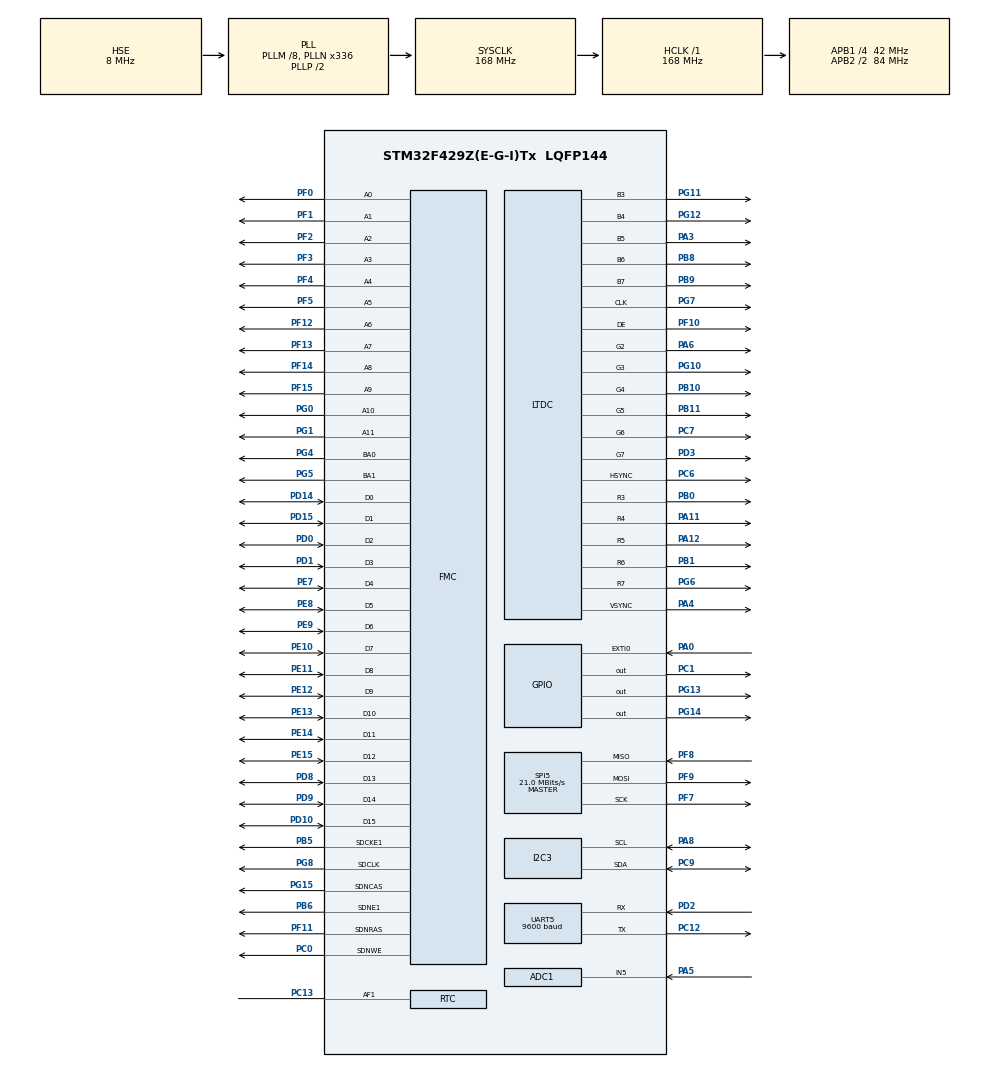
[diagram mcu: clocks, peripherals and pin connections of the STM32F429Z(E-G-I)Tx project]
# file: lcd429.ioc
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ADC1.Channel-20\#ChannelRegularConversion=ADC_CHANNEL_5
ADC1.Channel-28\#ChannelRegularConversion=ADC_CHANNEL_5
ADC1.Channel-29\#ChannelRegularConversion=ADC_CHANNEL_VBAT
ADC1.Channel-30\#ChannelRegularConversion=ADC_CHANNEL_VBAT
ADC1.ClockPrescaler=ADC_CLOCKPRESCALER_PCLK_DIV4
ADC1.ContinuousConvMode=ENABLE
ADC1.DMAContinuousRequests=ENABLE
ADC1.DataAlign=ADC_DATAALIGN_RIGHT
ADC1.DiscontinuousConvMode=DISABLE
ADC1.EOCSelection=EOC_SINGLE_CONV
ADC1.EnableAnalogWatchDog=false
ADC1.ExternalTrigConvEdge=ADC_EXTERNALTRIGCONVEDGE_NONE
ADC1.InjNumberOfConversion=0
ADC1.NbrOfConversion=4
ADC1.NbrOfConversionFlag=1
ADC1.Rank-20\#ChannelRegularConversion=1
ADC1.Rank-28\#ChannelRegularConversion=2
ADC1.Rank-29\#ChannelRegularConversion=3
ADC1.Rank-30\#ChannelRegularConversion=4
ADC1.Resolution=ADC_RESOLUTION12b
ADC1.SamplingTime-20\#ChannelRegularConversion=ADC_SAMPLETIME_3CYCLES
ADC1.SamplingTime-28\#ChannelRegularConversion=ADC_SAMPLETIME_3CYCLES
ADC1.SamplingTime-29\#ChannelRegularConversion=ADC_SAMPLETIME_3CYCLES
ADC1.SamplingTime-30\#ChannelRegularConversion=ADC_SAMPLETIME_3CYCLES
ADC1.ScanConvMode=ENABLE
ADC1.master=1
DMA2D.ColorMode=DMA2D_RGB565
DMA2D.Mode=DMA2D_R2M
Dma.ADC1.0.Channel=DMA_CHANNEL_0
Dma.ADC1.0.Direction=DMA_PERIPH_TO_MEMORY
Dma.ADC1.0.FIFOMode=DMA_FIFOMODE_DISABLE
Dma.ADC1.0.FIFOThreshold=DMA_FIFO_THRESHOLD_FULL
Dma.ADC1.0.Instance=DMA2_Stream0
Dma.ADC1.0.MemBurst=DMA_MBURST_SINGLE
Dma.ADC1.0.MemDataAlignment=DMA_MDATAALIGN_WORD
Dma.ADC1.0.MemInc=DMA_MINC_ENABLE
Dma.ADC1.0.Mode=DMA_NORMAL
Dma.ADC1.0.PeriphBurst=DMA_PBURST_SINGLE
Dma.ADC1.0.PeriphDataAlignment=DMA_PDATAALIGN_WORD
Dma.ADC1.0.PeriphInc=DMA_PINC_DISABLE
Dma.ADC1.0.Priority=DMA_PRIORITY_LOW
Dma.Request0=ADC1
FMC.CASLatency1=FMC_SDRAM_CAS_LATENCY_3
FMC.ExitSelfRefreshDelay1=7
FMC.LoadToActiveDelay1=2
FMC.RCDDelay1=2
FMC.RPDelay1=2
FMC.RPDelay2=2
FMC.RowBitsNumber1=FMC_SDRAM_ROW_BITS_NUM_12
FMC.RowCycleDelay1=7
FMC.RowCycleDelay2=7
FMC.SDClockPeriod1=FMC_SDRAM_CLOCK_PERIOD_2
FMC.SelfRefreshTime1=4
FMC.WriteRecoveryTime1=3
LTDC.ActiveH=320
LTDC.ActiveW=240
LTDC.Alpha_L0=255
LTDC.Alpha_L1=255
LTDC.BlendingFactor1_L0=LTDC_BLENDING_FACTOR1_PAxCA
LTDC.BlendingFactor1_L1=LTDC_BLENDING_FACTOR1_PAxCA
LTDC.BlendingFactor2_L0=LTDC_BLENDING_FACTOR2_PAxCA
LTDC.BlendingFactor2_L1=LTDC_BLENDING_FACTOR2_PAxCA
LTDC.FBStartAdress_L0=0xD0000000
LTDC.FBStartAdress_L1=0xD0025800
LTDC.HBP=29
LTDC.HFP=2
LTDC.HSync=9
LTDC.ImageHeight_L0=320
LTDC.ImageHeight_L1=320
LTDC.ImageWidth_L0=240
LTDC.ImageWidth_L1=240
LTDC.VBP=3
LTDC.VSync=1
LTDC.WindowX1_L0=240
LTDC.WindowX1_L1=240
LTDC.WindowY1_L0=320
LTDC.WindowY1_L1=320
Mcu.Family=STM32F4
Mcu.Name=STM32F429Z(E-G-I)Tx
Mcu.Package=LQFP144
NVIC.ADC_IRQn=true\:0\:0\:false
NVIC.DMA2_Stream0_IRQn=true\:0\:0\:false
NVIC.EXTI0_IRQn=true\:0\:0\:false
NVIC.PriorityGroup=NVIC_PRIORITYGROUP_4
PA0/WKUP.Signal=GPXTI0
PA11.Mode=RGB565
PA11.Signal=LTDC_R4
PA12.Mode=RGB565
PA12.Signal=LTDC_R5
PA3.Mode=RGB565
PA3.Signal=LTDC_B5
PA4.Mode=RGB565
PA4.Signal=LTDC_VSYNC
PA5.Signal=ADCx_IN5
PA6.Mode=RGB565
PA6.Signal=LTDC_G2
PA8.Mode=I2C
PA8.Signal=I2C3_SCL
PB0.Mode=RGB565
PB0.Signal=LTDC_R3
PB1.Mode=RGB565
PB1.Signal=LTDC_R6
PB10.Mode=RGB565
PB10.Signal=LTDC_G4
PB11.Mode=RGB565
PB11.Signal=LTDC_G5
PB5.Mode=SdramChipSelect2_1
PB5.Signal=FMC_SDCKE1
PB6.Mode=SdramChipSelect2_1
PB6.Signal=FMC_SDNE1
PB8.Mode=RGB565
PB8.Signal=LTDC_B6
PB9.Mode=RGB565
PB9.Signal=LTDC_B7
PC0.Signal=FMC_SDNWE
PC1.Signal=GPIO_Output
PC12.Mode=Asynchronous
PC12.Signal=UART5_TX
PC13.Mode=Timestamp enabled - Input Enabled to AF1
PC13.Signal=RTC_AF1
PC6.Mode=RGB565
PC6.Signal=LTDC_HSYNC
PC7.Mode=RGB565
PC7.Signal=LTDC_G6
PC9.Mode=I2C
PC9.Signal=I2C3_SDA
PD0.Signal=FMC_D2_DA2
PD1.Signal=FMC_D3_DA3
PD10.Signal=FMC_D15_DA15
PD14.Signal=FMC_D0_DA0
PD15.Signal=FMC_D1_DA1
PD2.Mode=Asynchronous
PD2.Signal=UART5_RX
PD3.Mode=RGB565
PD3.Signal=LTDC_G7
PD8.Signal=FMC_D13_DA13
PD9.Signal=FMC_D14_DA14
PE10.Signal=FMC_D7_DA7
PE11.Signal=FMC_D8_DA8
PE12.Signal=FMC_D9_DA9
PE13.Signal=FMC_D10_DA10
PE14.Signal=FMC_D11_DA11
PE15.Signal=FMC_D12_DA12
PE7.Signal=FMC_D4_DA4
PE8.Signal=FMC_D5_DA5
PE9.Signal=FMC_D6_DA6
PF0.Signal=FMC_A0
PF1.Signal=FMC_A1
PF10.Mode=RGB565
PF10.Signal=LTDC_DE
PF11.Signal=FMC_SDNRAS
PF12.Signal=FMC_A6
PF13.Signal=FMC_A7
PF14.Signal=FMC_A8
PF15.Signal=FMC_A9
PF2.Signal=FMC_A2
PF3.Signal=FMC_A3
PF4.Signal=FMC_A4
PF5.Signal=FMC_A5
PF7.Mode=Full_Duplex_Master
PF7.Signal=SPI5_SCK
PF8.Mode=Full_Duplex_Master
PF8.Signal=SPI5_MISO
PF9.Mode=Full_Duplex_Master
PF9.Signal=SPI5_MOSI
PG0.Signal=FMC_A10
PG1.Signal=FMC_A11
PG10.Mode=RGB565
PG10.Signal=LTDC_G3
PG11.Mode=RGB565
PG11.Signal=LTDC_B3
PG12.Mode=RGB565
PG12.Signal=LTDC_B4
PG13.Signal=GPIO_Output
PG14.Signal=GPIO_Output
PG15.Signal=FMC_SDNCAS
PG4.Signal=FMC_A14_BA0
PG5.Signal=FMC_A15_BA1
PG6.Mode=RGB565
PG6.Signal=LTDC_R7
PG7.Mode=RGB565
PG7.Signal=LTDC_CLK
PG8.Signal=FMC_SDCLK
PH0/OSC_IN.Mode=HSE-External-Oscillator
PH0/OSC_IN.Signal=RCC_OSC_IN
PH1/OSC_OUT.Mode=HSE-External-Oscillator
PH1/OSC_OUT.Signal=RCC_OSC_OUT
ProjectManager.TargetToolchain=MDK-ARM V5
RCC.48MHZClocksFreq_Value=84000000
RCC.AHBFreq_Value=168000000
RCC.APB1CLKDivider=RCC_HCLK_DIV4
RCC.APB1Freq_Value=42000000
RCC.APB1TimFreq_Value=84000000
RCC.APB2CLKDivider=RCC_HCLK_DIV2
RCC.APB2Freq_Value=84000000
RCC.APB2TimFreq_Value=168000000
RCC.CortexFreq_Value=168000000
RCC.HCLKFreq_Value=168000000
RCC.HSE_VALUE=8000000
RCC.HSI_VALUE=16000000
RCC.PLLM=8
RCC.PLLN=336
RCC.PLLSAIDivR=RCC_PLLSAIDIVR_4
RCC.PLLSAIN=192
RCC.PLLSAIR=5
RCC.PLLSourceVirtual=RCC_PLLSOURCE_HSE
RCC.SYSCLKFreq_VALUE=168000000
RCC.SYSCLKSource=RCC_SYSCLKSOURCE_PLLCLK
RCC.VCOOutputFreq_Value=336000000
RTC.Date=30
RTC.Format=FORMAT_BIN
RTC.Hours=12
RTC.Month=RTC_MONTH_DECEMBER
RTC.Year=15
SH.ADCx_IN5.0=ADC1_IN5,IN5
SH.FMC_A0.0=FMC_A0,12b-sda1
SH.FMC_A1.0=FMC_A1,12b-sda1
SH.FMC_A10.0=FMC_A10,12b-sda1
SH.FMC_A11.0=FMC_A11,12b-sda1
SH.FMC_A14_BA0.0=FMC_BA0,FourSdramBanks1
SH.FMC_A15_BA1.0=FMC_BA1,FourSdramBanks1
SH.FMC_A2.0=FMC_A2,12b-sda1
SH.FMC_A3.0=FMC_A3,12b-sda1
SH.FMC_A4.0=FMC_A4,12b-sda1
SH.FMC_A5.0=FMC_A5,12b-sda1
SH.FMC_A6.0=FMC_A6,12b-sda1
SH.FMC_A7.0=FMC_A7,12b-sda1
SH.FMC_A8.0=FMC_A8,12b-sda1
SH.FMC_A9.0=FMC_A9,12b-sda1
SH.FMC_D0_DA0.0=FMC_D0,sd-16b-d1
SH.FMC_D10_DA10.0=FMC_D10,sd-16b-d1
SH.FMC_D11_DA11.0=FMC_D11,sd-16b-d1
SH.FMC_D12_DA12.0=FMC_D12,sd-16b-d1
SH.FMC_D13_DA13.0=FMC_D13,sd-16b-d1
SH.FMC_D14_DA14.0=FMC_D14,sd-16b-d1
SH.FMC_D15_DA15.0=FMC_D15,sd-16b-d1
SH.FMC_D1_DA1.0=FMC_D1,sd-16b-d1
SH.FMC_D2_DA2.0=FMC_D2,sd-16b-d1
SH.FMC_D3_DA3.0=FMC_D3,sd-16b-d1
SH.FMC_D4_DA4.0=FMC_D4,sd-16b-d1
SH.FMC_D5_DA5.0=FMC_D5,sd-16b-d1
SH.FMC_D6_DA6.0=FMC_D6,sd-16b-d1
SH.FMC_D7_DA7.0=FMC_D7,sd-16b-d1
SH.FMC_D8_DA8.0=FMC_D8,sd-16b-d1
SH.FMC_D9_DA9.0=FMC_D9,sd-16b-d1
SH.FMC_SDCLK.0=FMC_SDCLK,12b-sda1
SH.FMC_SDNCAS.0=FMC_SDNCAS,12b-sda1
SH.FMC_SDNRAS.0=FMC_SDNRAS,12b-sda1
SH.FMC_SDNWE.0=FMC_SDNWE,12b-sda1
SPI5.BaudRatePrescaler=SPI_BAUDRATEPRESCALER_4
SPI5.CalculateBaudRate=21.0 MBits/s
SPI5.Mode=SPI_MODE_MASTER
UART5.BaudRate=9600
VP_ADC1_Vbat_Input.Mode=IN-Vbat
VP_DMA2D_VS_DMA2D.Mode=DMA2D_Activate
board=lcd429

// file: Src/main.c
/**
  ******************************************************************************
  * File Name          : main.c
  * Description        : Main program body
  ******************************************************************************
  *
  * COPYRIGHT(c) 2015 STMicroelectronics
  *
  * Redistribution and use in source and binary forms, with or without modification,
  * are permitted provided that the following conditions are met:
  *   1. Redistributions of source code must retain the above copyright notice,
  *      this list of conditions and the following disclaimer.
  *   2. Redistributions in binary form must reproduce the above copyright notice,
  *      this list of conditions and the following disclaimer in the documentation
  *      and/or other materials provided with the distribution.
  *   3. Neither the name of STMicroelectronics nor the names of its contributors
  *      may be used to endorse or promote products derived from this software
  *      without specific prior written permission.
  *
  * THIS SOFTWARE IS PROVIDED BY THE COPYRIGHT HOLDERS AND CONTRIBUTORS "AS IS"
  * AND ANY EXPRESS OR IMPLIED WARRANTIES, INCLUDING, BUT NOT LIMITED TO, THE
  * IMPLIED WARRANTIES OF MERCHANTABILITY AND FITNESS FOR A PARTICULAR PURPOSE ARE
  * DISCLAIMED. IN NO EVENT SHALL THE COPYRIGHT HOLDER OR CONTRIBUTORS BE LIABLE
  * FOR ANY DIRECT, INDIRECT, INCIDENTAL, SPECIAL, EXEMPLARY, OR CONSEQUENTIAL
  * DAMAGES (INCLUDING, BUT NOT LIMITED TO, PROCUREMENT OF SUBSTITUTE GOODS OR
  * SERVICES; LOSS OF USE, DATA, OR PROFITS; OR BUSINESS INTERRUPTION) HOWEVER
  * CAUSED AND ON ANY THEORY OF LIABILITY, WHETHER IN CONTRACT, STRICT LIABILITY,
  * OR TORT (INCLUDING NEGLIGENCE OR OTHERWISE) ARISING IN ANY WAY OUT OF THE USE
  * OF THIS SOFTWARE, EVEN IF ADVISED OF THE POSSIBILITY OF SUCH DAMAGE.
  *
  ******************************************************************************
  */
#include "stm32f4xx_hal.h"

/* USER CODE BEGIN Includes */
#include "pin.h"
#include "sdram.h"
#include "ili9341.h"
//#include "graph.h"
#include "l3gd20.h"
#include "itg3200.h"
#include "hmc5883.h"
#include "adxl345.h"
#include "compas.h"
#include "clinometer.h"
#include "guage.h"
#include "math.h"
#include "ff.h"
#include "image.h"

/* USER CODE END Includes */

ADC_HandleTypeDef hadc1;
DMA_HandleTypeDef hdma_adc1;

DMA2D_HandleTypeDef hdma2d;

I2C_HandleTypeDef hi2c3;

LTDC_HandleTypeDef hltdc;

RTC_HandleTypeDef hrtc;

SPI_HandleTypeDef hspi5;

UART_HandleTypeDef huart5;

SDRAM_HandleTypeDef hsdram1;

/* USER CODE BEGIN PV */
/* Private variables ---------------------------------------------------------*/

uint8_t flagButton;
char str[] = "1.0.1";
char bufStr[50] = "";
const char *directions[17]={"N","NNE","NE","ENE",
														"E","ESE","SE","SSE",
														"S","SSW","SW","WSW",
														"W","WNW","NW","NNW","N"};

__IO uint32_t TM_Time2;

/* USER CODE END PV */

void SystemClock_Config(void);
static void MX_GPIO_Init(void);
static void MX_DMA_Init(void);
static void MX_ADC1_Init(void);
static void MX_DMA2D_Init(void);
static void MX_FMC_Init(void);
static void MX_I2C3_Init(void);
static void MX_LTDC_Init(void);
static void MX_RTC_Init(void);
static void MX_SPI5_Init(void);
static void MX_UART5_Init(void);

/* USER CODE BEGIN PFP */
/* Private function prototypes -----------------------------------------------*/

/* USER CODE END PFP */

int main(void)
{

  /* USER CODE BEGIN 1 */
	uint8_t mode = 0, r, temp;
	uint8_t firsttime = 0, tosave = 0;
	uint32_t cur_tick, tmp_tick;
	//L3GD20_t lxyz;
	uint32_t i;
	XYZ_t ixyz, txyz;
	HMC_ID_StructTypeDef hres;
	int32_t tmp;
	int32_t tmpV, clV, valV;
	float angl;
	//uint16_t i;
  uint32_t adcData[5];

	FATFS FS;
	FRESULT fres;
	FATFS *fs;
	uint32_t Total; /*!< Total size of memory */
	uint32_t Free;  /*!< Free size of memory */

	DWORD fre_clust;

	DIR dir;
	FILINFO fno;

	FIL fil;
	UINT nWritten;
	UINT toWrite;
	UINT totalWrite;
	UINT totalWriten;

	BITMAPFILEHEADER bfh;
	BITMAPINFOHEADER bih;

	RTC_TimeTypeDef sTime;
	RTC_DateTypeDef sDate;

  /* USER CODE END 1 */

  /* MCU Configuration----------------------------------------------------------*/

  /* Reset of all peripherals, Initializes the Flash interface and the Systick. */
  HAL_Init();

  /* Configure the system clock */
  SystemClock_Config();

  /* Initialize all configured peripherals */
  MX_GPIO_Init();
  MX_DMA_Init();
  MX_ADC1_Init();
  MX_DMA2D_Init();
  MX_FMC_Init();
  MX_I2C3_Init();
  MX_LTDC_Init();
  MX_RTC_Init();
  MX_SPI5_Init();
  MX_UART5_Init();

  /* USER CODE BEGIN 2 */
	GPIO_HIGH(L3GD20_CS_PORT, L3GD20_CS_PIN);
	GPIO_HIGH(GPIOF, GPIO_PIN_6);//FATFS_CS_PORT, FATFS_CS_PIN

	//SPI_Init_Pins();

	SDRAM_InitPins();
 	SDRAM_Init(&hsdram1);
	//if (SDRAM_Init(&hsdram1)) GPIO_TOGGLE(GPIOG, GPIO_PIN_14);

	ILI9341_InitPins();
	ILI9341_Init();
	HAL_LTDC_SetAlpha(&hltdc, 255, 0);
	HAL_LTDC_SetAlpha(&hltdc, 0, 1);

	GRPH_Init();
	DMA2DGRPH_Fill();

	GRPH_DrawRect(0, 0, 239, 319);
//	GRPH_DrawLine(0,0,239,319);
//	GRPH_DrawLine(239,0,0,319);
//	GRPH_DrawCircle(120,160,60);

	DrawCompas(22, 297, 20, 0, 0);
	DrawClinometer(64, 297, 20, 0, 0);
	DrawGuageAbsolut(88, 297, 20, 100, 0, GRPH_COLOR_RED);

	GRPH_SetXY(200, 309);
	GRPH_Puts(str);

	HMC_Init(HMC_MR_CMM, HMC_DR_15, HMC_MM_Normal, HMC_GS_4_0, HMC_SS_1);
	L3GD20_Init(L3GD20_Scale_250);
	ITG_Init(ITG_DLPF_20_1, 0, ITG_CLK_GyroX);
	ADXL_Init();

	//HAL_ADC_Start(&hadc1);
	HAL_ADC_Start_DMA(&hadc1, adcData, 4);
	//ITG_SetChipAddr(0xd0);

//	if (f_mount(&FS, "0", 1) == FR_OK) {
//			fres = f_opendir(&dir, "/");
//			f_mount(NULL, "0", 1);
//	}

  /* USER CODE END 2 */

  /* Infinite loop */
  while (1)
  {

  /* USER CODE BEGIN 3 */

		cur_tick = HAL_GetTick();
		if (cur_tick - tmp_tick > 200){

			if (mode == 0 || mode == 1){

//				HAL_ADC_Start_DMA(&hadc1, adcData, 5);
				//HAL_ADC_GetValue(&hadc1);

				r = L3GD20_INT_ReadSPI(L3GD20_REG_WHO_AM_I);
				L3GD20_Read(&ixyz);
				sprintf(bufStr, "%02x %6d; %6d; %6d;", r, ixyz.X, ixyz.Y, ixyz.Z);
				//HAL_UART_Transmit(&huart5, (uint8_t *) bufStr, 50, 100);
				GRPH_SetXY(2, 3);
				GRPH_Puts(bufStr);

				r = ITG_GetChipAddr();
				ITG_GetXYZ(&ixyz);
				temp = ITG_GetTemperature();
				temp = ITG_ConvTemp(temp);
				sprintf(bufStr, "%02x %6d; %6d; %6d; %3d", r, ixyz.X, ixyz.Y, ixyz.Z, temp);
				GRPH_SetXY(2, 14);
				GRPH_Puts(bufStr);

				//GRPH_DrawPixel(80 + ixyz.X, 100 + ixyz.Y);

				HMC_GetId(&hres);
				HMC_GetXYZ(&ixyz);
				sprintf(bufStr, "%c%c%c %5d; %6d; %6d", hres.VALA, hres.VALB, hres.VALC, ixyz.X, ixyz.Y, ixyz.Z);
				GRPH_SetXY(2, 26);
				GRPH_Puts(bufStr);

				//DrawCompas(22, 297, 20, hxyz.X, hxyz.Y);
				DrawCompas(52, 100, 50, ixyz.X, ixyz.Y);

				angl = 270 + atan2(ixyz.Y, ixyz.X) * 180 /3.14;
				if (angl > 360) angl -= 360;
				tmp = (angl + 11)/22.5;
				sprintf(bufStr, "%4.1f %s      ", angl, directions[tmp]);
				GRPH_SetXY(2, 154);
				GRPH_Puts(bufStr);

				DrawGuage(107, 100, 50, ixyz.X, txyz.X, GRPH_COLOR_GREEN);
				DrawGuage(114, 100, 50, ixyz.Y, txyz.Y, GRPH_COLOR_BLUE);
				DrawGuage(121, 100, 50, ixyz.Z, txyz.Z, GRPH_COLOR_YELLOW);
				txyz.X = ixyz.X;
				txyz.Y = ixyz.Y;
				txyz.Z = ixyz.Z;

				r = ADXL_GetDeviceId();
				ADXL_GetXYZ(&ixyz);
				sprintf(bufStr, "%x %6d; %6d; %6d", r, ixyz.X, ixyz.Y, ixyz.Z);
				GRPH_SetXY(2, 38);
				GRPH_Puts(bufStr);
				//DrawClinometer(64, 297, 20, axyz.Y, 0);

				DrawClinometer(176, 100, 50, ixyz.X, ixyz.Y);

//				sprintf(bufStr, "%4x; %4x; %4x; %4x; %4x", adcData[0], adcData[1], adcData[2], adcData[3], adcData[4]);
//				//sprintf(bufStr, "%2.1fV %x     ", (3.3*(adcData[0]+adcData[1]+adcData[2]))/0x0fff/3, (adcData[0]+adcData[1]+adcData[2])/3);
//				GRPH_SetXY(2, 166);
//				GRPH_Puts(bufStr);
//
//				//sprintf(bufStr, "%4x; %4x; %4x; %4x; %4x", adcData[0], adcData[1], adcData[2], adcData[3], adcData[4]);
//				sprintf(bufStr, "%2.1fV %2.1fV     ", (3.3*(adcData[0]+adcData[1]+adcData[2]))/0x0fff/3, (3.3*(adcData[3]+adcData[4]))/0x0fff/2);
//				GRPH_SetXY(2, 178);
//				GRPH_Puts(bufStr);
//
//				if (adcData[0]> 0x500) clV = GRPH_COLOR_GREEN;
//				else  clV = GRPH_COLOR_RED;
//				valV = (adcData[0]+adcData[1]+adcData[2])/0x0f/3;
//				DrawBattery(220, 40, 10, valV, tmpV, clV);
//				tmpV = valV;

				HAL_RTC_GetTime(&hrtc, &sTime, RTC_FORMAT_BIN);
				HAL_RTC_SetDate(&hrtc, &sDate, RTC_FORMAT_BIN);

				sprintf(bufStr, "%04d%02d%02d %02d:%02d:%02d ", sDate.Year, sDate.Month, sDate.Date,
				 sTime.Hours, sTime.Minutes, sTime.Seconds);
				GRPH_SetXY(2, 190);
				GRPH_Puts(bufStr);

//				HAL_ADC_Stop_DMA(&hadc1);

				if (tosave == 1){
//					fres = img_save();
					//fres = f_mount(&FS, "SD:", 1);
					totalWrite = LCD_PIXEL_WIDTH * LCD_PIXEL_HEIGHT * LCD_PIXEL_SIZE;

					GPIO_TOGGLE(GPIOG, GPIO_PIN_14);

					//memset (&bfh, 0, sizeof(bfh));
					bfh.bfType = 0x4D42;
					bfh.bfOffBits = sizeof(bfh) + sizeof(bih);
					bfh.bfSize = bfh.bfOffBits + totalWrite;
					//memset (&bih, 0, sizeof(bih));
					bih.biSize = sizeof(bih);
					bih.biBitCount = 16;
					bih.biClrUsed = 0;
					bih.biCompression = 0;
					bih.biHeight = LCD_PIXEL_HEIGHT;
					bih.biWidth = LCD_PIXEL_WIDTH;
					bih.biPlanes = 1;
						//sprintf(bufStr, "pointer  %u", (uint32_t) &bfh);
						//GRPH_SetXY(2, 205);
						//GRPH_Puts(bufStr);

					fres = f_mount(&FS, "0", 1);
					if (fres == FR_OK) {
						//fres = img_save();

						//fres = f_open(&fil, "img.raw", FA_OPEN_ALWAYS | FA_READ | FA_WRITE);
						fres = f_open(&fil, "img.bmp", FA_OPEN_ALWAYS | FA_READ | FA_WRITE);
						if (fres == FR_OK) {

							//f_write(&fil, (uint8_t *) &bfh, sizeof(bfh), &nWritten);
							//f_write(&fil, (uint8_t *)(&bih), sizeof(bih), &nWritten);

							nWritten = 0;
							totalWriten = 0;
							toWrite = totalWrite;
							while (totalWrite > totalWriten){

								f_write(&fil, (uint8_t *)(LCD_FRAME_BUFFER + totalWriten), toWrite, &nWritten);
								toWrite -= nWritten;
								totalWriten += nWritten;
								nWritten = 0;

							}
							f_close(&fil);
						}

						f_mount(NULL, "0", 1);
					}
					if (fres == FR_OK) {
						sprintf(bufStr, "Write OK   ");
						GRPH_SetXY(2, 205);
						GRPH_Puts(bufStr);
					}else{
						sprintf(bufStr, "Error:  %u ", fres);
						GRPH_SetXY(2, 205);
						GRPH_Puts(bufStr);
					}
					//fres = img_bmp_save();
					tosave = 0;
				}

			}

			i++;
			if (i >= 10) i=0;

			GPIO_TOGGLE(GPIOG, GPIO_PIN_13);
			tmp_tick = cur_tick;
		}

		if (firsttime && mode == 1) {

			tosave = 1;

		}

		if (firsttime && mode == 3) {

			//fres = img_read();
			if (f_mount(&FS, "0", 1) == FR_OK) {

					fres = f_open(&fil, "img.raw", FA_OPEN_EXISTING | FA_READ );
					if (fres == FR_OK) {

							f_read(&fil, (uint8_t *)(LCD_FRAME_BUFFER), LCD_PIXEL_WIDTH*LCD_PIXEL_WIDTH*LCD_PIXEL_SIZE, &nWritten);

							/* Close file */
							f_close(&fil);

					}

					/* Unmount SDCARD */
					f_mount(NULL, "SD:", 1);
			}
			if (fres == FR_OK) {
				sprintf(bufStr, "Read OK  ");
				GRPH_SetXY(2, 205);
				GRPH_Puts(bufStr);

			}else{
				sprintf(bufStr, "Error:  %u ", fres);
				GRPH_SetXY(2, 205);
				GRPH_Puts(bufStr);
			}
		}

		if (firsttime && mode == 2) {

			//if (f_mount(&FS, "SD:", 1) == FR_OK) {
			if (f_mount(&FS, "0", 1) == FR_OK) {

					if (f_getfree("SD:", &fre_clust, &fs) == FR_OK) {
							Total = (fs->n_fatent - 2) * fs->csize * 0.5;
							Free = fre_clust * fs->csize * 0.5;
					}

					sprintf(bufStr, "Total: %u kBytes", Total);
					GRPH_SetXY(2, 3);
					GRPH_Puts(bufStr);
					sprintf(bufStr, "Free:  %u kBytes", Free);
					GRPH_SetXY(2, 14);
					GRPH_Puts(bufStr);

					i = 2;
					//fres = f_opendir(&dir, "SD:");
					fres = f_opendir(&dir, "/");
					if (fres == FR_OK) {
						while ((fres = f_readdir(&dir, &fno)) == FR_OK && fno.fname[0] != 0) {
							sprintf(bufStr, "%s - %u", fno.fname, fno.fsize);
							GRPH_SetXY(2, 12 * i + 3);
							GRPH_Puts(bufStr);
							i++;
						}
						f_closedir(&dir);
					}else{
						sprintf(bufStr, "Error:  %u ", fres);
						GRPH_SetXY(2, 12 * i + 3);
						GRPH_Puts(bufStr);
						i++;
					}

					/* Unmount SDCARD */
					f_mount(NULL, "SD:", 1);
			}
		}

		firsttime = 0;
		if (flagButton == 1){
			mode++;
			firsttime = 1;
      GPIO_TOGGLE(GPIOG, GPIO_PIN_14);
			flagButton = 0;

			DMA2DGRPH_Fill();

			GRPH_DrawRect(0,0,239,319);

			GRPH_SetXY(200, 309);
			GRPH_Puts(str);
		}

		if (mode == 4) mode = 0;
  }
  /* USER CODE END 3 */

}

/** System Clock Configuration
*/
void SystemClock_Config(void)
{

  RCC_OscInitTypeDef RCC_OscInitStruct;
  RCC_ClkInitTypeDef RCC_ClkInitStruct;
  RCC_PeriphCLKInitTypeDef PeriphClkInitStruct;

  __PWR_CLK_ENABLE();

  __HAL_PWR_VOLTAGESCALING_CONFIG(PWR_REGULATOR_VOLTAGE_SCALE1);

  RCC_OscInitStruct.OscillatorType = RCC_OSCILLATORTYPE_LSI|RCC_OSCILLATORTYPE_HSE;
  RCC_OscInitStruct.HSEState = RCC_HSE_ON;
  RCC_OscInitStruct.LSIState = RCC_LSI_ON;
  RCC_OscInitStruct.PLL.PLLState = RCC_PLL_ON;
  RCC_OscInitStruct.PLL.PLLSource = RCC_PLLSOURCE_HSE;
  RCC_OscInitStruct.PLL.PLLM = 8;
  RCC_OscInitStruct.PLL.PLLN = 336;
  RCC_OscInitStruct.PLL.PLLP = RCC_PLLP_DIV2;
  RCC_OscInitStruct.PLL.PLLQ = 4;
  HAL_RCC_OscConfig(&RCC_OscInitStruct);

  RCC_ClkInitStruct.ClockType = RCC_CLOCKTYPE_SYSCLK|RCC_CLOCKTYPE_PCLK1
                              |RCC_CLOCKTYPE_PCLK2;
  RCC_ClkInitStruct.SYSCLKSource = RCC_SYSCLKSOURCE_PLLCLK;
  RCC_ClkInitStruct.AHBCLKDivider = RCC_SYSCLK_DIV1;
  RCC_ClkInitStruct.APB1CLKDivider = RCC_HCLK_DIV4;
  RCC_ClkInitStruct.APB2CLKDivider = RCC_HCLK_DIV2;
  HAL_RCC_ClockConfig(&RCC_ClkInitStruct, FLASH_LATENCY_5);

  PeriphClkInitStruct.PeriphClockSelection = RCC_PERIPHCLK_LTDC|RCC_PERIPHCLK_RTC;
  PeriphClkInitStruct.PLLSAI.PLLSAIN = 192;
  PeriphClkInitStruct.PLLSAI.PLLSAIR = 5;
  PeriphClkInitStruct.PLLSAIDivR = RCC_PLLSAIDIVR_4;
  PeriphClkInitStruct.RTCClockSelection = RCC_RTCCLKSOURCE_LSI;
  HAL_RCCEx_PeriphCLKConfig(&PeriphClkInitStruct);

  HAL_SYSTICK_Config(HAL_RCC_GetHCLKFreq()/1000);

  HAL_SYSTICK_CLKSourceConfig(SYSTICK_CLKSOURCE_HCLK);

  /* SysTick_IRQn interrupt configuration */
  HAL_NVIC_SetPriority(SysTick_IRQn, 0, 0);
}

/* ADC1 init function */
void MX_ADC1_Init(void)
{

  ADC_ChannelConfTypeDef sConfig;

    /**Configure the global features of the ADC (Clock, Resolution, Data Alignment and number of conversion)
    */
  hadc1.Instance = ADC1;
  hadc1.Init.ClockPrescaler = ADC_CLOCKPRESCALER_PCLK_DIV4;
  hadc1.Init.Resolution = ADC_RESOLUTION12b;
  hadc1.Init.ScanConvMode = ENABLE;
  hadc1.Init.ContinuousConvMode = ENABLE;
  hadc1.Init.DiscontinuousConvMode = DISABLE;
  hadc1.Init.ExternalTrigConvEdge = ADC_EXTERNALTRIGCONVEDGE_NONE;
  hadc1.Init.DataAlign = ADC_DATAALIGN_RIGHT;
  hadc1.Init.NbrOfConversion = 4;
  hadc1.Init.DMAContinuousRequests = ENABLE;
  hadc1.Init.EOCSelection = EOC_SINGLE_CONV;
  HAL_ADC_Init(&hadc1);

    /**Configure for the selected ADC regular channel its corresponding rank in the sequencer and its sample time.
    */
  sConfig.Channel = ADC_CHANNEL_5;
  sConfig.Rank = 1;
  sConfig.SamplingTime = ADC_SAMPLETIME_3CYCLES;
  HAL_ADC_ConfigChannel(&hadc1, &sConfig);

    /**Configure for the selected ADC regular channel its corresponding rank in the sequencer and its sample time.
    */
  sConfig.Rank = 2;
  HAL_ADC_ConfigChannel(&hadc1, &sConfig);

    /**Configure for the selected ADC regular channel its corresponding rank in the sequencer and its sample time.
    */
  sConfig.Channel = ADC_CHANNEL_VBAT;
  sConfig.Rank = 3;
  HAL_ADC_ConfigChannel(&hadc1, &sConfig);

    /**Configure for the selected ADC regular channel its corresponding rank in the sequencer and its sample time.
    */
  sConfig.Rank = 4;
  HAL_ADC_ConfigChannel(&hadc1, &sConfig);

}

/* DMA2D init function */
void MX_DMA2D_Init(void)
{

  hdma2d.Instance = DMA2D;
  hdma2d.Init.Mode = DMA2D_R2M;
  hdma2d.Init.ColorMode = DMA2D_RGB565;
  hdma2d.Init.OutputOffset = 0;
  HAL_DMA2D_Init(&hdma2d);

}

/* I2C3 init function */
void MX_I2C3_Init(void)
{

  hi2c3.Instance = I2C3;
  hi2c3.Init.ClockSpeed = 100000;
  hi2c3.Init.DutyCycle = I2C_DUTYCYCLE_2;
  hi2c3.Init.OwnAddress1 = 0;
  hi2c3.Init.AddressingMode = I2C_ADDRESSINGMODE_7BIT;
  hi2c3.Init.DualAddressMode = I2C_DUALADDRESS_DISABLED;
  hi2c3.Init.OwnAddress2 = 0;
  hi2c3.Init.GeneralCallMode = I2C_GENERALCALL_DISABLED;
  hi2c3.Init.NoStretchMode = I2C_NOSTRETCH_DISABLED;
  HAL_I2C_Init(&hi2c3);

}

/* LTDC init function */
void MX_LTDC_Init(void)
{

  LTDC_LayerCfgTypeDef pLayerCfg;
  LTDC_LayerCfgTypeDef pLayerCfg1;

  hltdc.Instance = LTDC;
  hltdc.Init.HSPolarity = LTDC_HSPOLARITY_AL;
  hltdc.Init.VSPolarity = LTDC_VSPOLARITY_AL;
  hltdc.Init.DEPolarity = LTDC_DEPOLARITY_AL;
  hltdc.Init.PCPolarity = LTDC_PCPOLARITY_IPC;
  hltdc.Init.HorizontalSync = 8;
  hltdc.Init.VerticalSync = 0;
  hltdc.Init.AccumulatedHBP = 37;
  hltdc.Init.AccumulatedVBP = 3;
  hltdc.Init.AccumulatedActiveW = 277;
  hltdc.Init.AccumulatedActiveH = 323;
  hltdc.Init.TotalWidth = 279;
  hltdc.Init.TotalHeigh = 325;
  hltdc.Init.Backcolor.Blue = 0;
  hltdc.Init.Backcolor.Green = 0;
  hltdc.Init.Backcolor.Red = 0;
  HAL_LTDC_Init(&hltdc);

  pLayerCfg.WindowX0 = 0;
  pLayerCfg.WindowX1 = 240;
  pLayerCfg.WindowY0 = 0;
  pLayerCfg.WindowY1 = 320;
  pLayerCfg.PixelFormat = LTDC_PIXEL_FORMAT_RGB565;
  pLayerCfg.Alpha = 255;
  pLayerCfg.Alpha0 = 0;
  pLayerCfg.BlendingFactor1 = LTDC_BLENDING_FACTOR1_PAxCA;
  pLayerCfg.BlendingFactor2 = LTDC_BLENDING_FACTOR2_PAxCA;
  pLayerCfg.FBStartAdress = 0xD0000000;
  pLayerCfg.ImageWidth = 240;
  pLayerCfg.ImageHeight = 320;
  pLayerCfg.Backcolor.Blue = 0;
  pLayerCfg.Backcolor.Green = 0;
  pLayerCfg.Backcolor.Red = 0;
  HAL_LTDC_ConfigLayer(&hltdc, &pLayerCfg, 0);

  pLayerCfg1.WindowX0 = 0;
  pLayerCfg1.WindowX1 = 240;
  pLayerCfg1.WindowY0 = 0;
  pLayerCfg1.WindowY1 = 320;
  pLayerCfg1.PixelFormat = LTDC_PIXEL_FORMAT_RGB565;
  pLayerCfg1.Alpha = 255;
  pLayerCfg1.Alpha0 = 0;
  pLayerCfg1.BlendingFactor1 = LTDC_BLENDING_FACTOR1_PAxCA;
  pLayerCfg1.BlendingFactor2 = LTDC_BLENDING_FACTOR2_PAxCA;
  pLayerCfg1.FBStartAdress = 0xD0025800;
  pLayerCfg1.ImageWidth = 240;
  pLayerCfg1.ImageHeight = 320;
  pLayerCfg1.Backcolor.Blue = 0;
  pLayerCfg1.Backcolor.Green = 0;
  pLayerCfg1.Backcolor.Red = 0;
  HAL_LTDC_ConfigLayer(&hltdc, &pLayerCfg1, 1);

}

/* RTC init function */
void MX_RTC_Init(void)
{

  RTC_TimeTypeDef sTime;
  RTC_DateTypeDef sDate;

    /**Initialize RTC and set the Time and Date
    */
  hrtc.Instance = RTC;
  hrtc.Init.HourFormat = RTC_HOURFORMAT_24;
  hrtc.Init.AsynchPrediv = 127;
  hrtc.Init.SynchPrediv = 255;
  hrtc.Init.OutPut = RTC_OUTPUT_DISABLE;
  hrtc.Init.OutPutPolarity = RTC_OUTPUT_POLARITY_HIGH;
  hrtc.Init.OutPutType = RTC_OUTPUT_TYPE_OPENDRAIN;
  HAL_RTC_Init(&hrtc);

  sTime.Hours = 12;
  sTime.Minutes = 0;
  sTime.Seconds = 0;
  sTime.TimeFormat = RTC_HOURFORMAT12_AM;
  sTime.DayLightSaving = RTC_DAYLIGHTSAVING_NONE;
  sTime.StoreOperation = RTC_STOREOPERATION_RESET;
  HAL_RTC_SetTime(&hrtc, &sTime, FORMAT_BIN);

  sDate.WeekDay = RTC_WEEKDAY_MONDAY;
  sDate.Month = RTC_MONTH_DECEMBER;
  sDate.Date = 0x1E;
  sDate.Year = 0x0F;
  HAL_RTC_SetDate(&hrtc, &sDate, FORMAT_BIN);

    /**Enable the TimeStamp
    */
  HAL_RTCEx_SetTimeStamp(&hrtc, RTC_TIMESTAMPEDGE_RISING, RTC_TIMESTAMPPIN_PC13);

}

/* SPI5 init function */
void MX_SPI5_Init(void)
{

  hspi5.Instance = SPI5;
  hspi5.Init.Mode = SPI_MODE_MASTER;
  hspi5.Init.Direction = SPI_DIRECTION_2LINES;
  hspi5.Init.DataSize = SPI_DATASIZE_8BIT;
  hspi5.Init.CLKPolarity = SPI_POLARITY_LOW;
  hspi5.Init.CLKPhase = SPI_PHASE_1EDGE;
  hspi5.Init.NSS = SPI_NSS_SOFT;
  hspi5.Init.BaudRatePrescaler = SPI_BAUDRATEPRESCALER_4;
  hspi5.Init.FirstBit = SPI_FIRSTBIT_MSB;
  hspi5.Init.TIMode = SPI_TIMODE_DISABLED;
  hspi5.Init.CRCCalculation = SPI_CRCCALCULATION_DISABLED;
  hspi5.Init.CRCPolynomial = 10;
  HAL_SPI_Init(&hspi5);

}

/* UART5 init function */
void MX_UART5_Init(void)
{

  huart5.Instance = UART5;
  huart5.Init.BaudRate = 9600;
  huart5.Init.WordLength = UART_WORDLENGTH_8B;
  huart5.Init.StopBits = UART_STOPBITS_1;
  huart5.Init.Parity = UART_PARITY_NONE;
  huart5.Init.Mode = UART_MODE_TX_RX;
  huart5.Init.HwFlowCtl = UART_HWCONTROL_NONE;
  huart5.Init.OverSampling = UART_OVERSAMPLING_16;
  HAL_UART_Init(&huart5);

}

void MX_DMA_Init(void)
{
  /* DMA controller clock enable */
  __DMA2_CLK_ENABLE();

  /* DMA interrupt init */
  HAL_NVIC_SetPriority(DMA2_Stream0_IRQn, 0, 0);
  HAL_NVIC_EnableIRQ(DMA2_Stream0_IRQn);

}
/* FMC initialization function */
void MX_FMC_Init(void)
{
  FMC_SDRAM_TimingTypeDef SdramTiming;

  /** Perform the SDRAM1 memory initialization sequence
  */
  hsdram1.Instance = FMC_SDRAM_DEVICE;
  /* hsdram1.Init */
  hsdram1.Init.SDBank = FMC_SDRAM_BANK2;
  hsdram1.Init.ColumnBitsNumber = FMC_SDRAM_COLUMN_BITS_NUM_8;
  hsdram1.Init.RowBitsNumber = FMC_SDRAM_ROW_BITS_NUM_12;
  hsdram1.Init.MemoryDataWidth = FMC_SDRAM_MEM_BUS_WIDTH_16;
  hsdram1.Init.InternalBankNumber = FMC_SDRAM_INTERN_BANKS_NUM_4;
  hsdram1.Init.CASLatency = FMC_SDRAM_CAS_LATENCY_3;
  hsdram1.Init.WriteProtection = FMC_SDRAM_WRITE_PROTECTION_DISABLE;
  hsdram1.Init.SDClockPeriod = FMC_SDRAM_CLOCK_PERIOD_2;
  hsdram1.Init.ReadBurst = FMC_SDRAM_RBURST_DISABLE;
  hsdram1.Init.ReadPipeDelay = FMC_SDRAM_RPIPE_DELAY_0;
  /* SdramTiming */
  SdramTiming.LoadToActiveDelay = 2;
  SdramTiming.ExitSelfRefreshDelay = 7;
  SdramTiming.SelfRefreshTime = 4;
  SdramTiming.RowCycleDelay = 7;
  SdramTiming.WriteRecoveryTime = 3;
  SdramTiming.RPDelay = 2;
  SdramTiming.RCDDelay = 2;

  HAL_SDRAM_Init(&hsdram1, &SdramTiming);

}

/** Configure pins as
        * Analog
        * Input
        * Output
        * EVENT_OUT
        * EXTI
*/
void MX_GPIO_Init(void)
{

  GPIO_InitTypeDef GPIO_InitStruct;

  /* GPIO Ports Clock Enable */
  __GPIOC_CLK_ENABLE();
  __GPIOF_CLK_ENABLE();
  __GPIOH_CLK_ENABLE();
  __GPIOA_CLK_ENABLE();
  __GPIOB_CLK_ENABLE();
  __GPIOG_CLK_ENABLE();
  __GPIOE_CLK_ENABLE();
  __GPIOD_CLK_ENABLE();

  /*Configure GPIO pin : PC1 */
  GPIO_InitStruct.Pin = GPIO_PIN_1;
  GPIO_InitStruct.Mode = GPIO_MODE_OUTPUT_PP;
  GPIO_InitStruct.Pull = GPIO_NOPULL;
  GPIO_InitStruct.Speed = GPIO_SPEED_LOW;
  HAL_GPIO_Init(GPIOC, &GPIO_InitStruct);

  /*Configure GPIO pin : PA0 */
  GPIO_InitStruct.Pin = GPIO_PIN_0;
  GPIO_InitStruct.Mode = GPIO_MODE_IT_RISING;
  GPIO_InitStruct.Pull = GPIO_NOPULL;
  HAL_GPIO_Init(GPIOA, &GPIO_InitStruct);

  /*Configure GPIO pins : PG13 PG14 */
  GPIO_InitStruct.Pin = GPIO_PIN_13|GPIO_PIN_14;
  GPIO_InitStruct.Mode = GPIO_MODE_OUTPUT_PP;
  GPIO_InitStruct.Pull = GPIO_NOPULL;
  GPIO_InitStruct.Speed = GPIO_SPEED_LOW;
  HAL_GPIO_Init(GPIOG, &GPIO_InitStruct);

  /* EXTI interrupt init*/
  HAL_NVIC_SetPriority(EXTI0_IRQn, 0, 0);
  HAL_NVIC_EnableIRQ(EXTI0_IRQn);

}

/************************ (C) COPYRIGHT STMicroelectronics *****END OF FILE****/
